VERSION "3.7"

NS_ :

BS_:

BU_: Advantics_Charge_Controller Generic_Power_Modules

BO_ 2147921920 Advantics_Controller_Status: 1 Advantics_Charge_Controller
 SG_ State : 0|8@1+ (1,0) [0|0] "" Vector__XXX

BO_ 2147921921 New_Charge_Session: 2 Advantics_Charge_Controller
 SG_ Plug_and_pins : 8|8@1+ (1,0) [0|0] "" Vector__XXX
 SG_ Communication_Protocol : 0|8@1+ (1,0) [0|0] "" Vector__XXX

BO_ 2147921922 Charge_Status_Change: 1 Advantics_Charge_Controller
 SG_ Vehicle_Ready_for_Charging : 0|8@1+ (1,0) [0|0] "" Vector__XXX

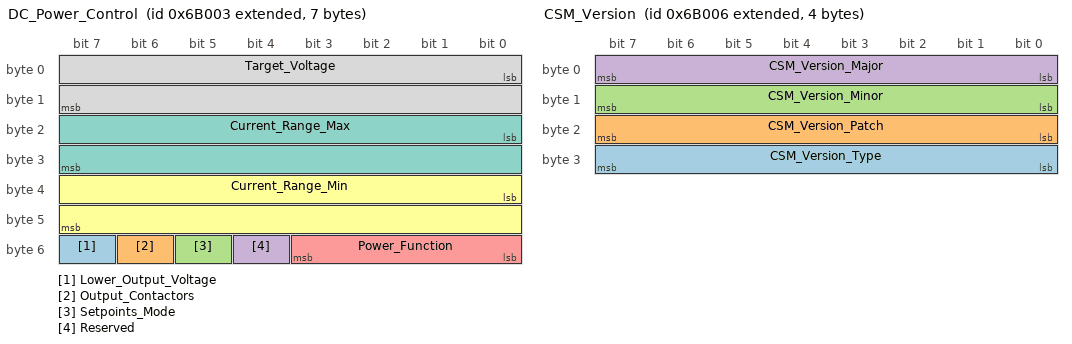
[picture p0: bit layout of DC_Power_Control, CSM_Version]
BO_ 2147921923 DC_Power_Control: 7 Advantics_Charge_Controller
 SG_ Lower_Output_Voltage : 55|1@1+ (1,0) [0|0] "" Vector__XXX
 SG_ Output_Contactors : 54|1@1+ (1,0) [0|0] "" Vector__XXX
 SG_ Setpoints_Mode : 53|1@1+ (1,0) [0|0] "" Vector__XXX
 SG_ Reserved : 52|1@1+ (1,0) [0|0] "" Vector__XXX
 SG_ Power_Function : 48|4@1+ (1,0) [0|0] "" Vector__XXX
 SG_ Current_Range_Min : 32|16@1- (0.1,0) [0|0] "Amps" Vector__XXX
 SG_ Current_Range_Max : 16|16@1- (0.1,0) [0|0] "Amps" Vector__XXX
 SG_ Target_Voltage : 0|16@1+ (0.1,0) [0|0] "Volts" Vector__XXX

BO_ 2147921924 Charge_Session_Finished: 1 Advantics_Charge_Controller
 SG_ State : 0|8@1+ (1,0) [0|0] "" Vector__XXX

BO_ 2147921925 Emergency_Stop: 1 Advantics_Charge_Controller
 SG_ Origin : 0|8@1+ (1,0) [0|0] "" Vector__XXX

BO_ 2147921926 CSM_Version: 4 Advantics_Charge_Controller
 SG_ CSM_Version_Type : 24|8@1+ (1,0) [0|0] "" Vector__XXX
 SG_ CSM_Version_Patch : 16|8@1+ (1,0) [0|0] "" Vector__XXX
 SG_ CSM_Version_Minor : 8|8@1+ (1,0) [0|0] "" Vector__XXX
 SG_ CSM_Version_Major : 0|8@1+ (1,0) [0|0] "" Vector__XXX

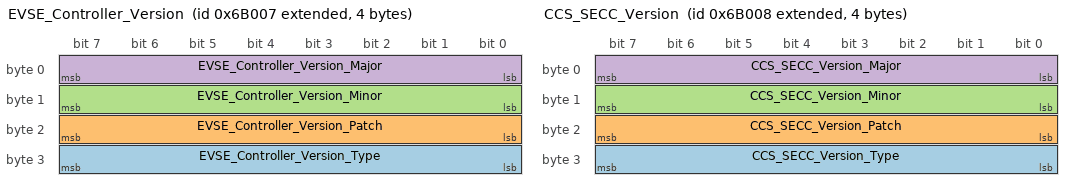
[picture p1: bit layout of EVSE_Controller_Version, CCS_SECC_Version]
BO_ 2147921927 EVSE_Controller_Version: 4 Advantics_Charge_Controller
 SG_ EVSE_Controller_Version_Type : 24|8@1+ (1,0) [0|0] "" Vector__XXX
 SG_ EVSE_Controller_Version_Patch : 16|8@1+ (1,0) [0|0] "" Vector__XXX
 SG_ EVSE_Controller_Version_Minor : 8|8@1+ (1,0) [0|0] "" Vector__XXX
 SG_ EVSE_Controller_Version_Major : 0|8@1+ (1,0) [0|0] "" Vector__XXX

BO_ 2147921928 CCS_SECC_Version: 4 Advantics_Charge_Controller
 SG_ CCS_SECC_Version_Type : 24|8@1+ (1,0) [0|0] "" Vector__XXX
 SG_ CCS_SECC_Version_Patch : 16|8@1+ (1,0) [0|0] "" Vector__XXX
 SG_ CCS_SECC_Version_Minor : 8|8@1+ (1,0) [0|0] "" Vector__XXX
 SG_ CCS_SECC_Version_Major : 0|8@1+ (1,0) [0|0] "" Vector__XXX

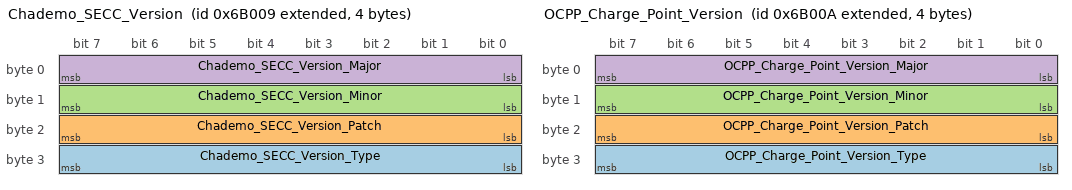
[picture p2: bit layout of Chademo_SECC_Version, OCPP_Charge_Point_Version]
BO_ 2147921929 Chademo_SECC_Version: 4 Advantics_Charge_Controller
 SG_ Chademo_SECC_Version_Type : 24|8@1+ (1,0) [0|0] "" Vector__XXX
 SG_ Chademo_SECC_Version_Patch : 16|8@1+ (1,0) [0|0] "" Vector__XXX
 SG_ Chademo_SECC_Version_Minor : 8|8@1+ (1,0) [0|0] "" Vector__XXX
 SG_ Chademo_SECC_Version_Major : 0|8@1+ (1,0) [0|0] "" Vector__XXX

BO_ 2147921930 OCPP_Charge_Point_Version: 4 Advantics_Charge_Controller
 SG_ OCPP_Charge_Point_Version_Type : 24|8@1+ (1,0) [0|0] "" Vector__XXX
 SG_ OCPP_Charge_Point_Version_Patch : 16|8@1+ (1,0) [0|0] "" Vector__XXX
 SG_ OCPP_Charge_Point_Version_Minor : 8|8@1+ (1,0) [0|0] "" Vector__XXX
 SG_ OCPP_Charge_Point_Version_Major : 0|8@1+ (1,0) [0|0] "" Vector__XXX

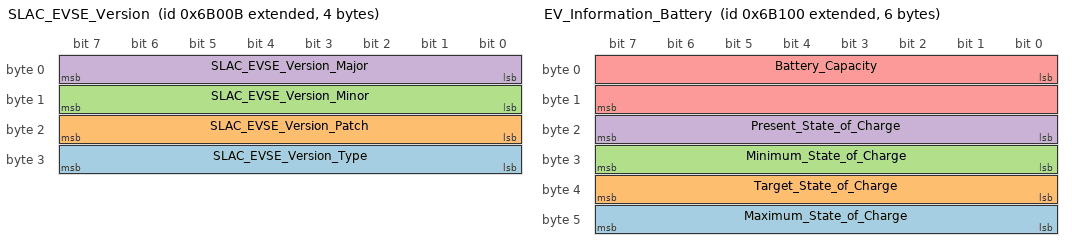
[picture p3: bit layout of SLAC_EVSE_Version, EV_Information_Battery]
BO_ 2147921931 SLAC_EVSE_Version: 4 Advantics_Charge_Controller
 SG_ SLAC_EVSE_Version_Type : 24|8@1+ (1,0) [0|0] "" Vector__XXX
 SG_ SLAC_EVSE_Version_Patch : 16|8@1+ (1,0) [0|0] "" Vector__XXX
 SG_ SLAC_EVSE_Version_Minor : 8|8@1+ (1,0) [0|0] "" Vector__XXX
 SG_ SLAC_EVSE_Version_Major : 0|8@1+ (1,0) [0|0] "" Vector__XXX

BO_ 2147922176 EV_Information_Battery: 6 Advantics_Charge_Controller
 SG_ Maximum_State_of_Charge : 40|8@1+ (1,0) [0|100] "%" Vector__XXX
 SG_ Target_State_of_Charge : 32|8@1+ (1,0) [0|100] "%" Vector__XXX
 SG_ Minimum_State_of_Charge : 24|8@1+ (1,0) [0|100] "%" Vector__XXX
 SG_ Present_State_of_Charge : 16|8@1+ (1,0) [0|100] "%" Vector__XXX
 SG_ Battery_Capacity : 0|16@1+ (1,0) [0|0] "kWh" Vector__XXX

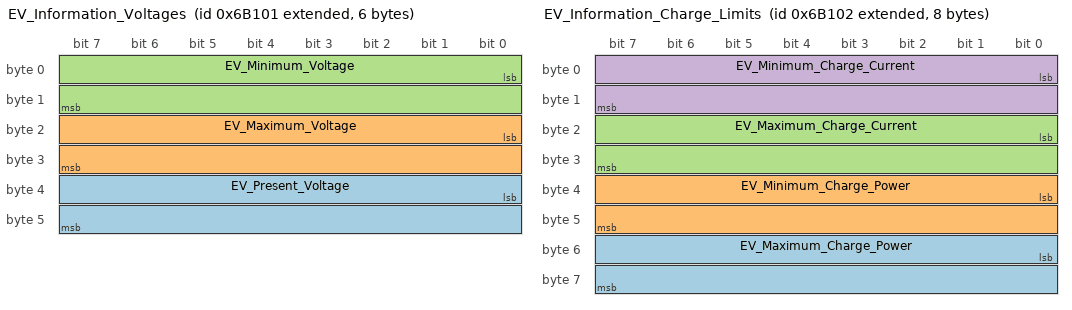
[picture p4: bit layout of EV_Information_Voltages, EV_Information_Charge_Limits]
BO_ 2147922177 EV_Information_Voltages: 6 Advantics_Charge_Controller
 SG_ EV_Present_Voltage : 32|16@1+ (0.1,0) [0|0] "Volts" Vector__XXX
 SG_ EV_Maximum_Voltage : 16|16@1+ (0.1,0) [0|0] "Volts" Vector__XXX
 SG_ EV_Minimum_Voltage : 0|16@1+ (0.1,0) [0|0] "Volts" Vector__XXX

BO_ 2147922178 EV_Information_Charge_Limits: 8 Advantics_Charge_Controller
 SG_ EV_Maximum_Charge_Power : 48|16@1+ (1,0) [0|0] "kW" Vector__XXX
 SG_ EV_Minimum_Charge_Power : 32|16@1+ (1,0) [0|0] "kW" Vector__XXX
 SG_ EV_Maximum_Charge_Current : 16|16@1+ (0.1,0) [0|0] "Amps" Vector__XXX
 SG_ EV_Minimum_Charge_Current : 0|16@1+ (0.1,0) [0|0] "Amps" Vector__XXX

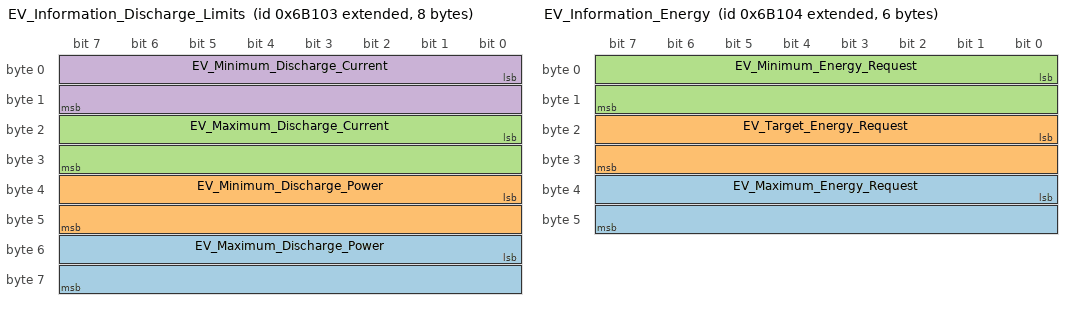
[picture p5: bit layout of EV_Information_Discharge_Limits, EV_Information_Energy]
BO_ 2147922179 EV_Information_Discharge_Limits: 8 Advantics_Charge_Controller
 SG_ EV_Maximum_Discharge_Power : 48|16@1+ (1,0) [0|0] "kW" Vector__XXX
 SG_ EV_Minimum_Discharge_Power : 32|16@1+ (1,0) [0|0] "kW" Vector__XXX
 SG_ EV_Maximum_Discharge_Current : 16|16@1+ (0.1,0) [0|0] "Amps" Vector__XXX
 SG_ EV_Minimum_Discharge_Current : 0|16@1+ (0.1,0) [0|0] "Amps" Vector__XXX

BO_ 2147922180 EV_Information_Energy: 6 Advantics_Charge_Controller
 SG_ EV_Maximum_Energy_Request : 32|16@1- (1,0) [0|0] "kWh" Vector__XXX
 SG_ EV_Target_Energy_Request : 16|16@1- (1,0) [0|0] "kWh" Vector__XXX
 SG_ EV_Minimum_Energy_Request : 0|16@1- (1,0) [0|0] "kWh" Vector__XXX

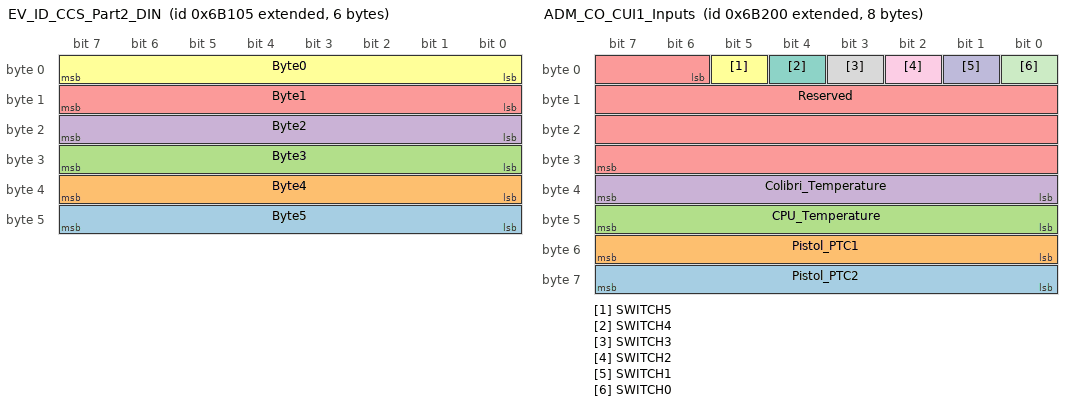
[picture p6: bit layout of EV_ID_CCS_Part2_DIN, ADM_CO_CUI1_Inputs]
BO_ 2147922181 EV_ID_CCS_Part2_DIN: 6 Advantics_Charge_Controller
 SG_ Byte5 : 40|8@1+ (1,0) [0|0] "" Vector__XXX
 SG_ Byte4 : 32|8@1+ (1,0) [0|0] "" Vector__XXX
 SG_ Byte3 : 24|8@1+ (1,0) [0|0] "" Vector__XXX
 SG_ Byte2 : 16|8@1+ (1,0) [0|0] "" Vector__XXX
 SG_ Byte1 : 8|8@1+ (1,0) [0|0] "" Vector__XXX
 SG_ Byte0 : 0|8@1+ (1,0) [0|0] "" Vector__XXX

BO_ 2147922432 ADM_CO_CUI1_Inputs: 8 Advantics_Charge_Controller
 SG_ Pistol_PTC2 : 56|8@1+ (1,-40) [-40|215] "°C" Vector__XXX
 SG_ Pistol_PTC1 : 48|8@1+ (1,-40) [-40|215] "°C" Vector__XXX
 SG_ CPU_Temperature : 40|8@1+ (1,-40) [-40|215] "°C" Vector__XXX
 SG_ Colibri_Temperature : 32|8@1+ (1,-40) [-40|215] "°C" Vector__XXX
 SG_ Reserved : 6|26@1+ (1,0) [0|0] "" Vector__XXX
 SG_ SWITCH5 : 5|1@1+ (1,0) [0|1] "" Vector__XXX
 SG_ SWITCH4 : 4|1@1+ (1,0) [0|1] "" Vector__XXX
 SG_ SWITCH3 : 3|1@1+ (1,0) [0|1] "" Vector__XXX
 SG_ SWITCH2 : 2|1@1+ (1,0) [0|1] "" Vector__XXX
 SG_ SWITCH1 : 1|1@1+ (1,0) [0|1] "" Vector__XXX
 SG_ SWITCH0 : 0|1@1+ (1,0) [0|1] "" Vector__XXX

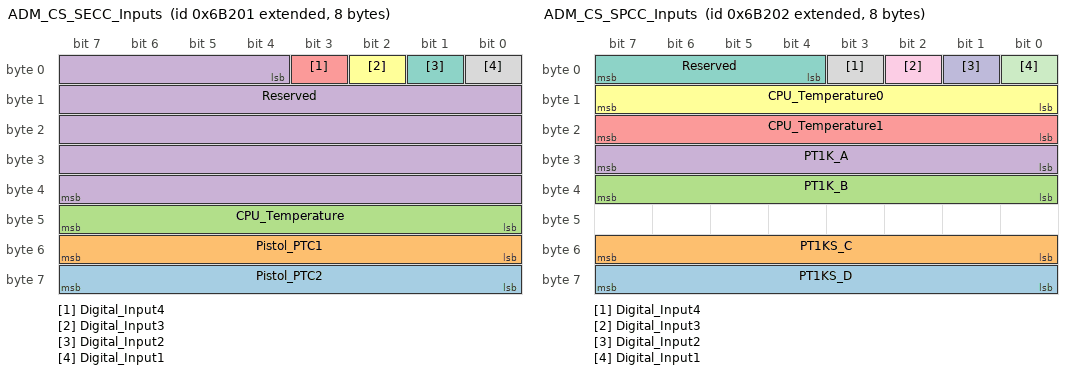
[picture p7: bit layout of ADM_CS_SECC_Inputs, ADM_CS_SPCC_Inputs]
BO_ 2147922433 ADM_CS_SECC_Inputs: 8 Advantics_Charge_Controller
 SG_ Pistol_PTC2 : 56|8@1+ (1,-40) [-40|215] "°C" Vector__XXX
 SG_ Pistol_PTC1 : 48|8@1+ (1,-40) [-40|215] "°C" Vector__XXX
 SG_ CPU_Temperature : 40|8@1+ (1,-40) [-40|215] "°C" Vector__XXX
 SG_ Reserved : 4|36@1+ (1,0) [0|0] "" Vector__XXX
 SG_ Digital_Input4 : 3|1@1+ (1,0) [0|1] "" Vector__XXX
 SG_ Digital_Input3 : 2|1@1+ (1,0) [0|1] "" Vector__XXX
 SG_ Digital_Input2 : 1|1@1+ (1,0) [0|1] "" Vector__XXX
 SG_ Digital_Input1 : 0|1@1+ (1,0) [0|1] "" Vector__XXX

BO_ 2147922434 ADM_CS_SPCC_Inputs: 8 Advantics_Charge_Controller
 SG_ PT1KS_D : 56|8@1+ (1,-40) [-40|215] "°C" Vector__XXX
 SG_ PT1KS_C : 48|8@1+ (1,-40) [-40|215] "°C" Vector__XXX
 SG_ PT1K_B : 32|8@1+ (1,-40) [-40|215] "°C" Vector__XXX
 SG_ PT1K_A : 24|8@1+ (1,-40) [-40|215] "°C" Vector__XXX
 SG_ CPU_Temperature1 : 16|8@1+ (1,-40) [-40|215] "°C" Vector__XXX
 SG_ CPU_Temperature0 : 8|8@1+ (1,-40) [-40|215] "°C" Vector__XXX
 SG_ Reserved : 4|4@1+ (1,0) [0|0] "" Vector__XXX
 SG_ Digital_Input4 : 3|1@1+ (1,0) [0|1] "" Vector__XXX
 SG_ Digital_Input3 : 2|1@1+ (1,0) [0|1] "" Vector__XXX
 SG_ Digital_Input2 : 1|1@1+ (1,0) [0|1] "" Vector__XXX
 SG_ Digital_Input1 : 0|1@1+ (1,0) [0|1] "" Vector__XXX

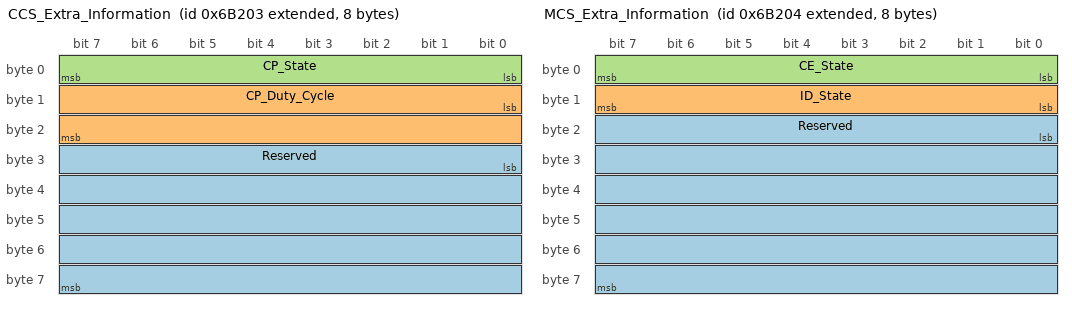
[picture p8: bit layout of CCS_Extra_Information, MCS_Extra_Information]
BO_ 2147922435 CCS_Extra_Information: 8 Advantics_Charge_Controller
 SG_ Reserved : 24|40@1+ (1,0) [0|0] "" Vector__XXX
 SG_ CP_Duty_Cycle : 8|16@1+ (0.1,0) [0|100] "%" Vector__XXX
 SG_ CP_State : 0|8@1+ (1,0) [0|0] "" Vector__XXX

BO_ 2147922436 MCS_Extra_Information: 8 Advantics_Charge_Controller
 SG_ Reserved : 16|48@1+ (1,0) [0|0] "" Vector__XXX
 SG_ ID_State : 8|8@1+ (1,0) [0|0] "" Vector__XXX
 SG_ CE_State : 0|8@1+ (1,0) [0|0] "" Vector__XXX

BO_ 2147922688 OCPP_Control: 2 Advantics_Charge_Controller
 SG_ Dynamic_Target_Current : 0|16@1- (0.1,0) [0|0] "Amps" Vector__XXX

BO_ 2147922944 Charger_Diagnostic_Status: 8 Advantics_Charge_Controller
 SG_ Reserved_Flags : 35|29@1+ (1,0) [0|0] "" Vector__XXX
 SG_ PowerPermitWithdrawn : 34|1@1+ (1,0) [0|0] "" Vector__XXX
 SG_ SessionStoppedBeforeCharge : 33|1@1+ (1,0) [0|0] "" Vector__XXX
 SG_ EVChargingSystemIncompatibility : 32|1@1+ (1,0) [0|0] "" Vector__XXX
 SG_ EVChargingVoltageOutOfRange : 31|1@1+ (1,0) [0|0] "" Vector__XXX
 SG_ EVChargingCurrentDifferential : 30|1@1+ (1,0) [0|0] "" Vector__XXX
 SG_ EVRESSMalfunction : 29|1@1+ (1,0) [0|0] "" Vector__XXX
 SG_ EVConnectorLockFault : 28|1@1+ (1,0) [0|0] "" Vector__XXX
 SG_ EVShiftPosition : 27|1@1+ (1,0) [0|0] "" Vector__XXX
 SG_ EVRESSTemperatureInhibit : 26|1@1+ (1,0) [0|0] "" Vector__XXX
 SG_ CommunicationSetupTimeout : 25|1@1+ (1,0) [0|0] "" Vector__XXX
 SG_ V2GProtocolNotAllowed : 24|1@1+ (1,0) [0|0] "" Vector__XXX
 SG_ V2GParameterNotSupported : 23|1@1+ (1,0) [0|0] "" Vector__XXX
 SG_ V2GSessionIDUnexpected : 22|1@1+ (1,0) [0|0] "" Vector__XXX
 SG_ V2GSequenceError : 21|1@1+ (1,0) [0|0] "" Vector__XXX
 SG_ ChargeEnableStateUnexpected : 20|1@1+ (1,0) [0|0] "" Vector__XXX
 SG_ ChargeEnableFault : 19|1@1+ (1,0) [0|0] "" Vector__XXX
 SG_ ControlPilotStateUnexpected : 18|1@1+ (1,0) [0|0] "" Vector__XXX
 SG_ ControlPilotFault : 17|1@1+ (1,0) [0|0] "" Vector__XXX
 SG_ BidirectionalNotSupported : 16|1@1+ (1,0) [0|0] "" Vector__XXX
 SG_ RangeModeNotSupported : 15|1@1+ (1,0) [0|0] "" Vector__XXX
 SG_ CANBusError : 14|1@1+ (1,0) [0|0] "" Vector__XXX
 SG_ NodeDisconnected : 13|1@1+ (1,0) [0|0] "" Vector__XXX
 SG_ InternalError : 12|1@1+ (1,0) [0|0] "" Vector__XXX
 SG_ ChargerSequenceError : 11|1@1+ (1,0) [0|0] "" Vector__XXX
 SG_ HighTemperature : 10|1@1+ (1,0) [0|0] "" Vector__XXX
 SG_ PowerModuleRampDownTimeout : 9|1@1+ (1,0) [0|0] "" Vector__XXX
 SG_ PowerModuleDisabled : 8|1@1+ (1,0) [0|0] "" Vector__XXX
 SG_ PowerModuleCANTimeout : 7|1@1+ (1,0) [0|0] "" Vector__XXX
 SG_ PowerModuleFault : 6|1@1+ (1,0) [0|0] "" Vector__XXX
 SG_ InsulationMonitorFault : 5|1@1+ (1,0) [0|0] "" Vector__XXX
 SG_ InsulationFault : 4|1@1+ (1,0) [0|0] "" Vector__XXX
 SG_ ConnectorLockFailure : 3|1@1+ (1,0) [0|0] "" Vector__XXX
 SG_ OutputDriverFault : 2|1@1+ (1,0) [0|0] "" Vector__XXX
 SG_ EmergencyStopLoopOpen : 1|1@1+ (1,0) [0|0] "" Vector__XXX
 SG_ InterlockFault : 0|1@1+ (1,0) [0|0] "" Vector__XXX

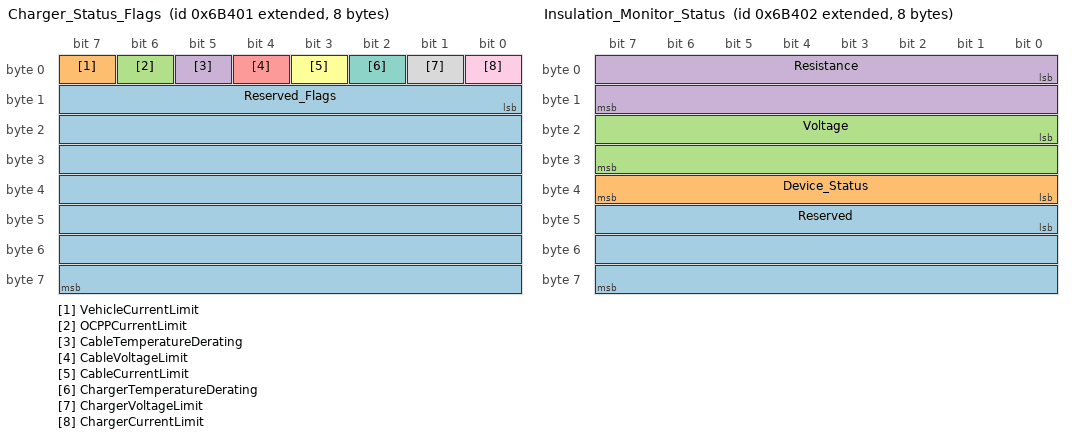
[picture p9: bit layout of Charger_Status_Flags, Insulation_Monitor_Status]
BO_ 2147922945 Charger_Status_Flags: 8 Advantics_Charge_Controller
 SG_ Reserved_Flags : 8|56@1+ (1,0) [0|0] "" Vector__XXX
 SG_ VehicleCurrentLimit : 7|1@1+ (1,0) [0|0] "" Vector__XXX
 SG_ OCPPCurrentLimit : 6|1@1+ (1,0) [0|0] "" Vector__XXX
 SG_ CableTemperatureDerating : 5|1@1+ (1,0) [0|0] "" Vector__XXX
 SG_ CableVoltageLimit : 4|1@1+ (1,0) [0|0] "" Vector__XXX
 SG_ CableCurrentLimit : 3|1@1+ (1,0) [0|0] "" Vector__XXX
 SG_ ChargerTemperatureDerating : 2|1@1+ (1,0) [0|0] "" Vector__XXX
 SG_ ChargerVoltageLimit : 1|1@1+ (1,0) [0|0] "" Vector__XXX
 SG_ ChargerCurrentLimit : 0|1@1+ (1,0) [0|0] "" Vector__XXX

BO_ 2147922946 Insulation_Monitor_Status: 8 Advantics_Charge_Controller
 SG_ Reserved : 40|24@1+ (1,0) [0|0] "" Vector__XXX
 SG_ Device_Status : 32|8@1+ (1,0) [0|0] "" Vector__XXX
 SG_ Voltage : 16|16@1+ (1,0) [0|0] "Volts" Vector__XXX
 SG_ Resistance : 0|16@1+ (1,0) [0|0] "kOhms" Vector__XXX

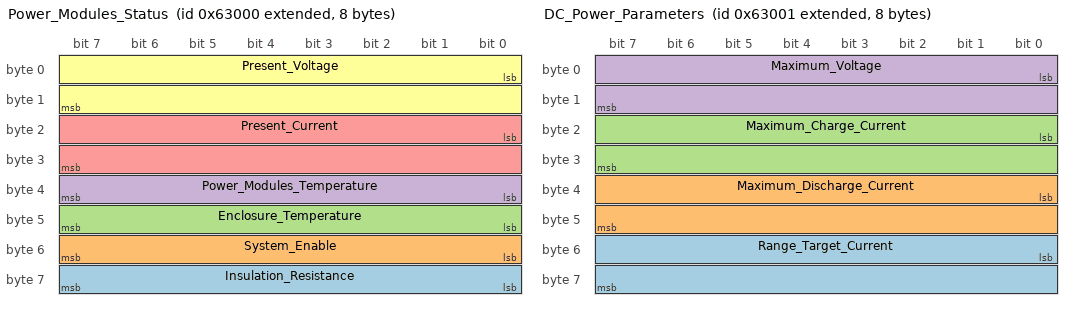
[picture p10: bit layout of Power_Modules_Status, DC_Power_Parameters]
BO_ 2147889152 Power_Modules_Status: 8 Generic_Power_Modules
 SG_ Insulation_Resistance : 56|8@1+ (2,0) [0|0] "kOhms" Vector__XXX
 SG_ System_Enable : 48|8@1+ (1,0) [0|0] "" Vector__XXX
 SG_ Enclosure_Temperature : 40|8@1+ (1,-40) [-40|215] "°C" Vector__XXX
 SG_ Power_Modules_Temperature : 32|8@1+ (1,-40) [-40|215] "°C" Vector__XXX
 SG_ Present_Current : 16|16@1- (0.1,0) [0|0] "Amps" Vector__XXX
 SG_ Present_Voltage : 0|16@1+ (0.1,0) [0|0] "Volts" Vector__XXX

BO_ 2147889153 DC_Power_Parameters: 8 Generic_Power_Modules
 SG_ Range_Target_Current : 48|16@1- (0.1,0) [0|0] "Amps" Vector__XXX
 SG_ Maximum_Discharge_Current : 32|16@1+ (0.1,0) [0|0] "Amps" Vector__XXX
 SG_ Maximum_Charge_Current : 16|16@1+ (0.1,0) [0|0] "Amps" Vector__XXX
 SG_ Maximum_Voltage : 0|16@1+ (0.1,0) [0|0] "Volts" Vector__XXX

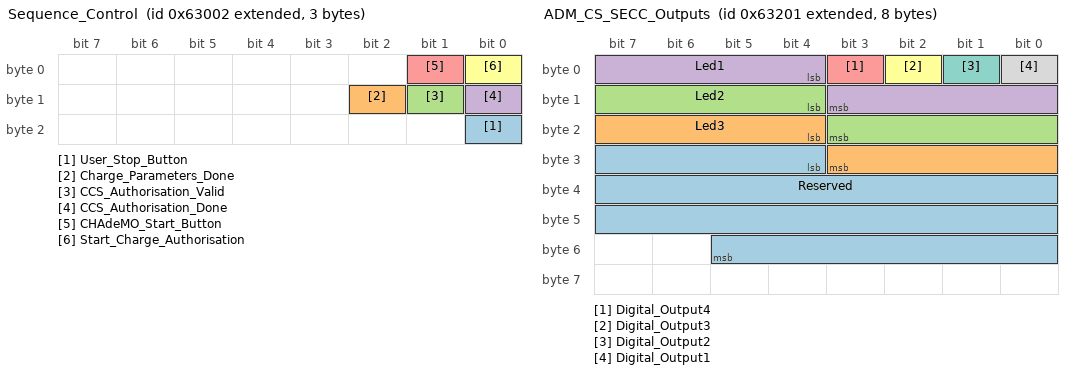
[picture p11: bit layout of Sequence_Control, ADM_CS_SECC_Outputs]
BO_ 2147889154 Sequence_Control: 3 Generic_Power_Modules
 SG_ User_Stop_Button : 16|1@1+ (1,0) [0|0] "" Vector__XXX
 SG_ Charge_Parameters_Done : 10|1@1+ (1,0) [0|0] "" Vector__XXX
 SG_ CCS_Authorisation_Valid : 9|1@1+ (1,0) [0|0] "" Vector__XXX
 SG_ CCS_Authorisation_Done : 8|1@1+ (1,0) [0|0] "" Vector__XXX
 SG_ CHAdeMO_Start_Button : 1|1@1+ (1,0) [0|0] "" Vector__XXX
 SG_ Start_Charge_Authorisation : 0|1@1+ (1,0) [0|0] "" Vector__XXX

BO_ 2147889665 ADM_CS_SECC_Outputs: 8 Generic_Power_Modules
 SG_ Reserved : 28|26@1+ (1,0) [0|0] "" Vector__XXX
 SG_ Led3 : 20|8@1+ (1,0) [0|255] "" Vector__XXX
 SG_ Led2 : 12|8@1+ (1,0) [0|255] "" Vector__XXX
 SG_ Led1 : 4|8@1+ (1,0) [0|255] "" Vector__XXX
 SG_ Digital_Output4 : 3|1@1+ (1,0) [0|1] "" Vector__XXX
 SG_ Digital_Output3 : 2|1@1+ (1,0) [0|1] "" Vector__XXX
 SG_ Digital_Output2 : 1|1@1+ (1,0) [0|1] "" Vector__XXX
 SG_ Digital_Output1 : 0|1@1+ (1,0) [0|1] "" Vector__XXX

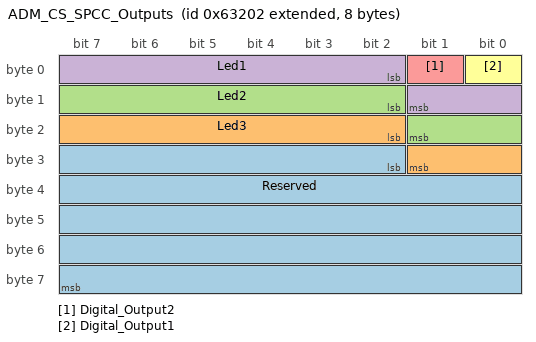
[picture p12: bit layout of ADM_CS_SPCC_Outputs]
BO_ 2147889666 ADM_CS_SPCC_Outputs: 8 Generic_Power_Modules
 SG_ Reserved : 26|38@1+ (1,0) [0|0] "" Vector__XXX
 SG_ Led3 : 18|8@1+ (1,0) [0|255] "" Vector__XXX
 SG_ Led2 : 10|8@1+ (1,0) [0|255] "" Vector__XXX
 SG_ Led1 : 2|8@1+ (1,0) [0|255] "" Vector__XXX
 SG_ Digital_Output2 : 1|1@1+ (1,0) [0|1] "" Vector__XXX
 SG_ Digital_Output1 : 0|1@1+ (1,0) [0|1] "" Vector__XXX

CM_ BO_ 2147921920 "
                Periodic message reporting the current status of the controller. This message is
                sent all the time as soon as the application on the controller is running.

                IMPORTANT: Power modules should implement a timeout on the reception of this message.
                If the controller does not send this message within 200 ms, then power modules
                should consider the controller to be in a defective state and stop any power function
                as soon as possible.
            ";
CM_ SG_ 2147921920 State "
                    Current internal state. For information only.

                    Initialising:: Controller's applications are starting up.
                    Waiting_For_PEV:: Controller is idle and ready for a plug-in.
                    Negotiating_Connection:: Controller is plugged to a car and the connection is
                        being initialised. Important charge information are exchanged.
                    Connected_With_Full_Info:: All charge information from the PEV were retrieved
                        and a charge session can be considered to be properly open.
                    Insulation_Test:: Insulation of the charge cable is being tested.
                    Precharge:: Charger is matching its output voltage to the present voltage of the
                        battery.
                    Waiting_For_Charge:: PEV is about to begin the actual charging.
                    Charging:: Main charging loop going on.
                    Ending_Charge:: A normal charge stop condition happenned and the PEV is exiting
                        the charging loop.
                    Welding_Detection:: PEV is testing if its contactors are welded.
                    Closing_Communication:: PEV can unplug and charger is reinitialising in order to
                        then go back to __Waiting_For_PEV__.
                    CCS_Authorisation_Process:: Special state in CCS to authorise user.
                    Not_Available:: Controller has been made unavailable by
                        __Sequence_Control.Start_Charge_Authorisation__
                ";
CM_ BO_ 2147921921 "
                Information about an incoming vehicle. Sent periodically from the moment a car is
                plugged in and all the information are known. Until power modules send a
                <<Power_Modules_Status.System_Enable>> with value  __Allowed__.
            ";
CM_ SG_ 2147921921 Plug_and_pins "Plug type and DC pins selected by the car.";
CM_ SG_ 2147921921 Communication_Protocol "The charging protocol the car is using.";
CM_ BO_ 2147921922 "
                Signal a change in the charging procedure. Sent once only when something change.
            ";
CM_ SG_ 2147921922 Vehicle_Ready_for_Charging "
                    Tells when the vehicle intend to start or stop the charge.

                    If value is __Charge_Started__, the power modules must be ready for the
                    charging loop at any moment (with CCS it can still be in several hours).

                    When value is __Charge_Stopped__, the vehicle stopped the charging process.
                ";
CM_ BO_ 2147921923 "
                Sent during any powered phase of a DC charge session. This message contains the
                power function in use, setpoint targets or range, the setpoints mode, the output
                contactors and voltage lowering commands.

                # Power function

                The power function currently in use is given by <<DC_Power_Control.Power_Function>>.
                It covers the off state, standby, insulation test, precharge and the actual power
                transfer.

                During __Standby__, power modules should disable any power processing function (ie.
                turn off), but not bleed their output capacitors (ie. leave the output floating) as
                a load might be connected at that time, unless otherwise commanded by
                <<DC_Power_Control.Lower_Output_Voltage>>.

                During __Insulation_Test__, the insulation of the cable is tested by applying a
                voltage from the charger. The battery is not connected yet. The test voltage to
                apply is given by <<DC_Power_Control.Target_Voltage>>. Power modules report
                <<Power_Modules_Status.Present_Voltage>> and <<Power_Modules_Status.Insulation_Resistance>>
                and the controller decides when the test passes or fails. Safety standards require a
                minimum of 100 Ohms/V insulation resistance. With a typical test voltage of 500 V,
                insulation resistance should be >= 50 kOhms. Maximum current to use is not specified.

                During __Precharge__ (CCS only), charger is expected to match battery voltage at its
                output while having no load, apart from capacitors on the line. When charging this
                capacitive load, it shall not output more current than <<DC_Power_Control.Current_Range_Max>>.
                The battery voltage to match is given by <<DC_Power_Control.Target_Voltage>>. The
                vehicle decides to consider precharge done when it senses on its inlet a voltage that
                is +/- 20 V of its battery voltage.

                During __Power_Transfer__, actual power is being transfered in one direction or
                another. The meaning of setpoints depends on <<DC_Power_Control.Setpoints_Mode>>.
                The transfer direction depends on the sign of current setpoints, with positive
                meaning power being delivered to the vehicle (ie. charge). And negative meaning
                power extracted from the vehicle (ie. discharge).

                NOTE: While targets and ranges are expressed in both voltage and current, it is up
                to power modules to determine which control mode they should use (ie. constant current,
                constant voltage or constant power) depending on the present situation, and the load
                attached to their output. Charging protocols do not define it. In a typical situation,
                insulation tests and precharge have to be controlled in Constant Voltage. Whereas,
                when a battery is connected to the charger output, the vehicle BMS specifies the
                maximum current to be delivered to it, or consummed from it. Which makes it a
                Constant Current process. But you might also encounter a vehicle with a different
                pack voltage (eg. 800 V), and using a DC/DC in between the charger output and its
                battery to convert the voltage. In such case, you might have to run into Constant
                Voltage mode for instance.

                # Setpoints mode

                Either the vehicle control the current to be delivered or consummed (that's
                __Target_Mode__). Or, a range of acceptable values is given, and power modules are
                free to operate within that range (that's __Range_Mode__).

                In the simplest (historical) case, power transfer is unidirectional, with the
                vehicle requesting a certain amount of current for a target voltage, and power
                modules have to deliver that current. __Target_Mode__ is used in that case.
                And both min and max of the range have the same value. If you do less current than
                requested, some vehicle might accept it, and some might terminate the charge on a
                current deviation error. <<Power_Transfer_Parameters.Maximum_Charge_Current>> offers
                a way to dynamically \"negotiate\" a lower current request properly.

                If the vehicle and/or charging protocol wants to use limits instead of targets (eg.
                CHAdeMO V2G, or ISO 15118-20 in Dynamic mode), then __Range_Mode__ is used. The min
                and max of the range are given, and power modules can choose the actual load and
                power transfer direction within that range.

                Note however that, if in your application power modules are not able to decide of
                the load by themselves, then you can treat the maximum of the range as the target
                setpoint (which is why the same signal is used for both target and maximum).

                During a power transfer, the setpoint mode does not change between range or target.
                However, during the rest of the session, for consistency, during __Insulation_Test__
                it will be __Target_Mode__. And during __Precharge__ it will be __Range_Mode__.
                During other power functions it is not relevant.

                # Bidirectional power transfers

                Bidirectional power transfers are only possible when both the vehicle and the charger
                supports it (on charger side, `is_bidirectional` has to be set to True in the config
                file for that pistol). Bidirectional power transfer can happen either in
                __Range_Mode__ (power modules choose when to switch over) or __Target_Mode__ (vehicle
                decides when it is time to charge or discharge its battery). Bidirectional in range
                mode would typically happen with CHAdeMO V2G, or ISO 15118-20 in Dynamic mode.
                Whereas birectional in target mode would happen with ISO 15118-20 in Scheduled mode.

                When in range mode, a portion of the range will be in the negative values (or all of
                it if only discharge is possible). Note that the positive portion of the range, used
                for charging, naturally follows min and max charge current values. Whereas the
                negative portion of the range, used for discharging, is mirrored, and its min and
                max are logically inverted. Said differently <<DC_Power_Control.Current_Range_Min>>
                shows the maximum discharge current, but with a negative sign. And
                <<DC_Power_Control.Current_Range_Max>> shows the maximum charge current with a
                positive sign.

                In the particular situation only discharge is possible, the minimum of the range is
                still the maximum discharge current with a negative sign. And the maximum of the
                range is then the minimum discharge current, also with a negative sign.

                As such, you can see this range as a \"continuous slider\" on which you can pick an
                operating point, moving between the maximum discharge current (the min), and the
                maximum charge current (the max). With 0 as a midpoint (but not necessarily
                symmetric). If no discharge is possible, then the min is positive. And if no charge
                is possible, then the max is negative.

                WARNING: The vehicle might not necessarily ramps up or down its requests.
            ";
CM_ SG_ 2147921923 Lower_Output_Voltage "
                    Tells when charger output voltage should forcibly be lowered to less than or
                    equal to 20 V. It can be done, for instance, by bleeding the voltage of power
                    modules output capacitors.

                    Can only happen in __Standby__ function, with voltage and current setpoints set
                    to 0.

                    Output voltage lowering is requested at the following points in the charge
                    session:

                    - After insulation test, and before precharge (CCS) or power transfer (CHAdeMO).
                      In this case, the controller does not command output contactors to open by
                      itself (ie. using its onboard relay) as they would have to reclose shortly
                      after. It will however wait that output voltage lower to <= 20 V to comply
                      with charging standards.
                    - After power transfer, when <<Advantics_Controller_Status.State>> is
                      __Ending_Charge__, current has lowered to less than 1 A, and after having
                      opened output contactors. In this case, the controller does not need to wait
                      for voltage to lower. Note that at this point the vehicle battery might still
                      be connected to pistol pins (hence why it does not wait on the voltage). Which
                      means if your charger does not have output contactors, you should actually
                      avoid bleeding output capacitors at this point, and ignore the lowering request.
                    - When entering <<Advantics_Controller_Status.State>> == __Closing_Communication__
                      if output voltage is above 20 V. It could happen after a welding detection
                      process from the vehicle in case there are no output contactors and output
                      capacitors are still charged (or got recharged during welding detection). This
                      lowering request is for safety, in order to avoid exposing high voltages on
                      the pistol contacts once it gets unplugged from the vehicle.
                ";
CM_ SG_ 2147921923 Output_Contactors "
                    Reflects contactors control done using controller's onboard relay.
                ";
CM_ SG_ 2147921923 Setpoints_Mode "
                    Defines how power modules should follow setpoints.

                    __Target_Mode__: Power transfer is controlled by the vehicle, and power modules
                    should follow the given targets. Min and max of the range have the same value.

                    __Range_Mode__: All parties provide ranges of acceptable limits, and the
                    controller gives a merged view of that range. Power modules are then free to
                    provide or draw power within that range.
                ";
CM_ SG_ 2147921923 Reserved "Reserved bits for future uses.";
CM_ SG_ 2147921923 Power_Function "
                    This signal describes the sort of power function expected from power modules at
                    a particular point in the process.

                    __Off__: Power modules turn off any power processing function. And the output of
                    the charger (exposed on the pistol pins) has ~0 V, floating.

                    __Standby__: Power modules do not run any power processing function, while
                    remaining ready to receive future requests. A load might still be connected to
                    their output. Therefore, unless comanded by <<DC_Power_Control.Lower_Output_Voltage>>,
                    it should remain floating, with contactors still closed, and no discharge of
                    their output capacitors should be attempted.

                    __Insulation_Test__: Power modules (or an external dedicated safety module) apply
                    high voltage and measure the current leaked through ground. The test voltage
                    reaches up to the vehicle, but its input contactors are still open.

                    __Precharge__: Power modules match the requested voltage while limiting their
                    output current (only some capacitance should be charged during this process).
                    The purpose is to avoid arcing when vehicle contactors close.
                    Precharge is specific to CCS. In CHAdeMO you either have a diode at the output
                    of the charger (unidirectional). Or a custom precharge circuit around the main
                    output contactors (bidirectionnal, or unidirectional made without diode).

                    __Power_Transfer__: Main mode of operation, as power is being transfered in one
                    way or another. See the documentation of <<DC_Power_Control.Setpoints_Mode>> and
                    others signals of this message for more details.
                ";
CM_ SG_ 2147921923 Current_Range_Min "
                    Maximum current to draw (if negative), or minimum current to provide (if positive).

                    In __Target_Mode__, this signal will have the same value than
                    <<DC_Power_Control.Current_Range_Max>>.

                    In __Insulation_Test__, this signal is not relevant.

                    In __Precharge__, this signal is 0 A.

                    In __Power_Transfer__, this signal gives the minimum of the current range to use.
                ";
CM_ SG_ 2147921923 Current_Range_Max "
                    Maximum current to provide (if positive), or minimum current to draw (if negative).

                    In __Target_Mode__, this signal should be used as the target current setpoint.

                    In __Insulation_Test__, this signal is not relevant.

                    In __Precharge__, this signal carries the maximum current the vehicle wants
                    charger to respect. Usually a value between 0 and 2 A.

                    In __Power_Transfer__, this signal gives the maximum of the current range to use.
                ";
CM_ SG_ 2147921923 Target_Voltage "
                    Voltage setpoint.

                    In __Insulation_Test__, this is the test voltage, and it should corresponds to
                    the maximum voltage a charger can theoretically deliver during a charge session.
                    At the end of the test, this setpoint is set back to 0 V.

                    In __Precharge__, it usually corresponds to the real battery voltage (unless the
                    vehicle uses an intermediate DC/DC).

                    In __Power_Transfer__, it usually corresponds to a voltage significantly higher
                    than the battery voltage (implying a Constant Current process). However, if the
                    vehicle uses an intermediate DC/DC, then it corresponds to the input voltage of
                    that DC/DC.
                ";
CM_ BO_ 2147921924 "Charging is over and the vehicle should unplug soon.";
CM_ SG_ 2147921924 State "Was the session terminated cleanly or not.";
CM_ BO_ 2147921925 "
                Sent from the moment an emergency stop has been triggered.

                Emergency_Stop are not explicitly rearmable. You either power cycle the whole setup.
                Or the emergency condition disappear, and the message will stop being sent once the
                controller pass in a state where it reevaluates emergency conditions.
            ";
CM_ SG_ 2147921925 Origin "From which side the emergency stop came from.";
CM_ BO_ 2147921926 "
                Reports the software version of the CSM (Charge Station Management) application.

                Sent periodically once the application is running. Versions rarely change (a new
                version requires restarting the application), so a slow polling interval on the
                receiving side is fine.
            ";
CM_ SG_ 2147921926 CSM_Version_Type "Release type of the CSM application version.";
CM_ SG_ 2147921926 CSM_Version_Patch "Patch version number of the CSM application.";
CM_ SG_ 2147921926 CSM_Version_Minor "Minor version number of the CSM application.";
CM_ SG_ 2147921926 CSM_Version_Major "Major version number of the CSM application.";
CM_ BO_ 2147921927 "
                Reports the software version of the EVSE controller application itself.

                Sent periodically once the application is running. Versions rarely change (a new
                version requires restarting the application), so a slow polling interval on the
                receiving side is fine.
            ";
CM_ SG_ 2147921927 EVSE_Controller_Version_Type "Release type of the EVSE controller application version.";
CM_ SG_ 2147921927 EVSE_Controller_Version_Patch "Patch version number of the EVSE controller application.";
CM_ SG_ 2147921927 EVSE_Controller_Version_Minor "Minor version number of the EVSE controller application.";
CM_ SG_ 2147921927 EVSE_Controller_Version_Major "Major version number of the EVSE controller application.";
CM_ BO_ 2147921928 "
                Reports the software version of the CCS SECC (Supply Equipment Communication
                Controller) application.

                Sent periodically once the application is running. Only relevant on installations
                that have CCS enabled; otherwise reported as 0.0.0.
            ";
CM_ SG_ 2147921928 CCS_SECC_Version_Type "Release type of the CCS SECC application version.";
CM_ SG_ 2147921928 CCS_SECC_Version_Patch "Patch version number of the CCS SECC application.";
CM_ SG_ 2147921928 CCS_SECC_Version_Minor "Minor version number of the CCS SECC application.";
CM_ SG_ 2147921928 CCS_SECC_Version_Major "Major version number of the CCS SECC application.";
CM_ BO_ 2147921929 "
                Reports the software version of the CHAdeMO SECC (Supply Equipment Communication
                Controller) application.

                Sent periodically once the application is running. Only relevant on installations
                that have CHAdeMO enabled; otherwise reported as 0.0.0.
            ";
CM_ SG_ 2147921929 Chademo_SECC_Version_Type "Release type of the CHAdeMO SECC application version.";
CM_ SG_ 2147921929 Chademo_SECC_Version_Patch "Patch version number of the CHAdeMO SECC application.";
CM_ SG_ 2147921929 Chademo_SECC_Version_Minor "Minor version number of the CHAdeMO SECC application.";
CM_ SG_ 2147921929 Chademo_SECC_Version_Major "Major version number of the CHAdeMO SECC application.";
CM_ BO_ 2147921930 "
                Reports the software version of the OCPP charge point application.

                Sent periodically once the application is running. Versions rarely change (a new
                version requires restarting the application), so a slow polling interval on the
                receiving side is fine.
            ";
CM_ SG_ 2147921930 OCPP_Charge_Point_Version_Type "Release type of the OCPP charge point application version.";
CM_ SG_ 2147921930 OCPP_Charge_Point_Version_Patch "Patch version number of the OCPP charge point application.";
CM_ SG_ 2147921930 OCPP_Charge_Point_Version_Minor "Minor version number of the OCPP charge point application.";
CM_ SG_ 2147921930 OCPP_Charge_Point_Version_Major "Major version number of the OCPP charge point application.";
CM_ BO_ 2147921931 "
                Reports the software version of the SLAC (Signal Level Attenuation
                Characterization) EVSE application.

                Sent periodically once the application is running. Versions rarely change (a new
                version requires restarting the application), so a slow polling interval on the
                receiving side is fine.
            ";
CM_ SG_ 2147921931 SLAC_EVSE_Version_Type "Release type of the SLAC EVSE application version.";
CM_ SG_ 2147921931 SLAC_EVSE_Version_Patch "Patch version number of the SLAC EVSE application.";
CM_ SG_ 2147921931 SLAC_EVSE_Version_Minor "Minor version number of the SLAC EVSE application.";
CM_ SG_ 2147921931 SLAC_EVSE_Version_Major "Major version number of the SLAC EVSE application.";
CM_ BO_ 2147922176 "
                Vehicle battery information.

                Sent at least once after first <<New_Charge_Session>> message. As well as every time
                vehicle changes these information.

                Many of these information can be optional. There default value is 0 if the vehicle
                did not sent them.
            ";
CM_ SG_ 2147922176 Maximum_State_of_Charge "Maximum battery SoC vehicle wants, in percent.";
CM_ SG_ 2147922176 Target_State_of_Charge "Target battery SoC vehicle wants, in percent.";
CM_ SG_ 2147922176 Minimum_State_of_Charge "Minimum battery SoC vehicle wants, in percent.";
CM_ SG_ 2147922176 Present_State_of_Charge "Battery SoC, in percent.";
CM_ SG_ 2147922176 Battery_Capacity "Total battery capacity.";
CM_ BO_ 2147922177 "
                Vehicle voltages information.

                Sent at least once after first <<New_Charge_Session>> message. As well as every time
                vehicle changes these information.

                Many of these information can be optional. There default value is 0 if the vehicle
                did not sent them.
            ";
CM_ SG_ 2147922177 EV_Present_Voltage "
                    Present voltage reported by vehicle.

                    Note: Can be use in Constant Voltage mode to compensate for cable losses.
                ";
CM_ SG_ 2147922177 EV_Maximum_Voltage "Maximum vehicle voltage.";
CM_ SG_ 2147922177 EV_Minimum_Voltage "Minimum vehicle voltage.";
CM_ BO_ 2147922178 "
                Vehicle information for current and power limits during charging.

                Sent at least once after first <<New_Charge_Session>> message. As well as every time
                vehicle changes these information.

                Many of these information can be optional. There default value is 0 if the vehicle
                did not sent them.
            ";
CM_ SG_ 2147922178 EV_Maximum_Charge_Power "Maximum vehicle charge power.";
CM_ SG_ 2147922178 EV_Minimum_Charge_Power "Minimum vehicle charge power.";
CM_ SG_ 2147922178 EV_Maximum_Charge_Current "Maximum vehicle charge current.";
CM_ SG_ 2147922178 EV_Minimum_Charge_Current "Minimum vehicle charge current.";
CM_ BO_ 2147922179 "
                Vehicle information for current and power limits during discharging.

                Sent at least once after first <<New_Charge_Session>> message. As well as every time
                vehicle changes these information.

                Many of these information can be optional. There default value is 0 if the vehicle
                did not sent them.
            ";
CM_ SG_ 2147922179 EV_Maximum_Discharge_Power "Maximum vehicle discharge power.";
CM_ SG_ 2147922179 EV_Minimum_Discharge_Power "Minimum vehicle discharge power.";
CM_ SG_ 2147922179 EV_Maximum_Discharge_Current "Maximum vehicle discharge current.";
CM_ SG_ 2147922179 EV_Minimum_Discharge_Current "Minimum vehicle discharge current.";
CM_ BO_ 2147922180 "
                Vehicle information for energy.

                Sent at least once after first <<New_Charge_Session>> message. As well as every time
                vehicle changes these information.

                Many of these information can be optional. There default value is 0 if the vehicle
                did not sent them.
            ";
CM_ SG_ 2147922180 EV_Maximum_Energy_Request "
                    Maximum (estimated) remaining energy vehicle will consumme (positive value),
                    or provide (negative value).
                ";
CM_ SG_ 2147922180 EV_Target_Energy_Request "
                    Targeted (estimated) remaining energy vehicle will consumme (positive value),
                    or provide (negative value).
                ";
CM_ SG_ 2147922180 EV_Minimum_Energy_Request "
                    Minimum (estimated) remaining energy vehicle will consumme (positive value),
                    or provide (negative value).
                ";
CM_ BO_ 2147922181 "
                The EV ID provided by the vehicle in CCS DIN SPEC 70121 and ISO 15118-2.
                EV ID for CCS ISO 15118-20 is not supported by this message.
                (the EV ID is defined as a string of max 255 characters in ISO 15118-20)
            ";
CM_ SG_ 2147922181 Byte5 "
                    Byte 5 of the EV ID.
                ";
CM_ SG_ 2147922181 Byte4 "
                    Byte 4 of the EV ID.
                ";
CM_ SG_ 2147922181 Byte3 "
                    Byte 3 of the EV ID.
                ";
CM_ SG_ 2147922181 Byte2 "
                    Byte 2 of the EV ID.
                ";
CM_ SG_ 2147922181 Byte1 "
                    Byte 1 of the EV ID.
                ";
CM_ SG_ 2147922181 Byte0 "
                    Byte 0 of the EV ID.
                ";
CM_ BO_ 2147922432 "
                Controller (ADM-CO-CUI1 hardware variant, ie. \"generic/mobile\") is reporting various
                information about its inputs. It is sent every seconds (for temperature channels).
                Or on change for other digital inputs.
            ";
CM_ SG_ 2147922432 Pistol_PTC2 "Measured temperature sensor on second PTC channel associated to this pistol.";
CM_ SG_ 2147922432 Pistol_PTC1 "Measured temperature sensor on first PTC channel associated to this pistol.";
CM_ SG_ 2147922432 CPU_Temperature "Temperature reported by the CPU chip of the charge controller.";
CM_ SG_ 2147922432 Colibri_Temperature "Temperature measured on the Colibri SoM board of the charge controller.";
CM_ SG_ 2147922432 Reserved "Reserved bits for future uses.";
CM_ SG_ 2147922432 SWITCH5 "
                    Reports the logical state of SWITCH5 (J7, position 6).
                    Needs to be declared as monitored in `/srv/config.cfg`:

                        [hardware]
                        switch5 = Monitor
                ";
CM_ SG_ 2147922432 SWITCH4 "
                    Reports the logical state of SWITCH4 (J7, position 5).
                    Needs to be declared as monitored in `/srv/config.cfg`:

                        [hardware]
                        switch4 = Monitor
                ";
CM_ SG_ 2147922432 SWITCH3 "
                    Reports the logical state of SWITCH3 (J7, position 4).
                    Needs to be declared as monitored in `/srv/config.cfg`:

                        [hardware]
                        switch3 = Monitor
                ";
CM_ SG_ 2147922432 SWITCH2 "
                    Reports the logical state of SWITCH2 (J7, position 3).
                    Needs to be declared as monitored in `/srv/config.cfg`:

                        [hardware]
                        switch2 = Monitor
                ";
CM_ SG_ 2147922432 SWITCH1 "
                    Reports the logical state of SWITCH1 (J7, position 2).
                    Needs to be declared as monitored in `/srv/config.cfg`:

                        [hardware]
                        switch1 = Monitor
                ";
CM_ SG_ 2147922432 SWITCH0 "
                    Reports the logical state of SWITCH0 (J7, position 1).
                    Needs to be declared as monitored in `/srv/config.cfg`:

                        [hardware]
                        switch0 = Monitor
                ";
CM_ BO_ 2147922433 "
                Controller (ADM-CS-SECC hardware variant, ie. \"DIN rail\") is reporting various
                information about its inputs. It is sent every seconds (for temperature channels).
                Or on change for other digital inputs.
            ";
CM_ SG_ 2147922433 Pistol_PTC2 "Measured temperature sensor on second PTC channel associated to this pistol.";
CM_ SG_ 2147922433 Pistol_PTC1 "Measured temperature sensor on first PTC channel associated to this pistol.";
CM_ SG_ 2147922433 CPU_Temperature "Temperature reported by the CPU chip of the charge controller.";
CM_ SG_ 2147922433 Reserved "Reserved bits for future uses.";
CM_ SG_ 2147922433 Digital_Input4 "
                    Reports the logical state of DIG_IN4 (CONN6, position 4).
                    Needs to be declared as monitored in `/srv/config.cfg`:

                        [hardware]
                        dig_in4 = Monitor
                ";
CM_ SG_ 2147922433 Digital_Input3 "
                    Reports the logical state of DIG_IN3 (CONN6, position 3).
                    Needs to be declared as monitored in `/srv/config.cfg`:

                        [hardware]
                        dig_in3 = Monitor
                ";
CM_ SG_ 2147922433 Digital_Input2 "
                    Reports the logical state of DIG_IN2 (CONN6, position 2).
                    Needs to be declared as monitored in `/srv/config.cfg`:

                        [hardware]
                        dig_in2 = Monitor
                ";
CM_ SG_ 2147922433 Digital_Input1 "
                    Reports the logical state of DIG_IN1 (CONN6, position 1).
                    Needs to be declared as monitored in `/srv/config.cfg`:

                        [hardware]
                        dig_in1 = Monitor
                ";
CM_ BO_ 2147922434 "
                Controller (ADM-CS-SPCC hardware variant) is reporting various
                information about its inputs. It is sent every seconds (for temperature channels).
                Or on change for other digital inputs.
            ";
CM_ SG_ 2147922434 PT1KS_D "Measured temperature sensor on PT1KS_D input.";
CM_ SG_ 2147922434 PT1KS_C "Measured temperature sensor on PT1KS_C input.";
CM_ SG_ 2147922434 PT1K_B "Measured temperature sensor on PT1K_B input.";
CM_ SG_ 2147922434 PT1K_A "
                This input is used as CHAdeMO pistol solenoid input when the controller is configured for CHAdeMO.
                When the controller is configured for MCS, CCS DC or AC, this input can be used as a temperature sensor.
                ";
CM_ SG_ 2147922434 CPU_Temperature1 "Temperature reported by the CPU chip of the charge controller.";
CM_ SG_ 2147922434 CPU_Temperature0 "Temperature reported by the CPU chip of the charge controller.";
CM_ SG_ 2147922434 Reserved "Reserved bits for future uses.";
CM_ SG_ 2147922434 Digital_Input4 "
                    Reports the logical state of DIG_IN4 (CONN6, position 4).
                    Needs to be declared as monitored in `/srv/config.cfg`:

                        [hardware]
                        dig_in4 = Monitor
                ";
CM_ SG_ 2147922434 Digital_Input3 "
                    Reports the logical state of DIG_IN3 (CONN6, position 3).
                    Needs to be declared as monitored in `/srv/config.cfg`:

                        [hardware]
                        dig_in3 = Monitor
                ";
CM_ SG_ 2147922434 Digital_Input2 "
                    Reports the logical state of DIG_IN2 (CONN6, position 2).
                    Needs to be declared as monitored in `/srv/config.cfg`:

                        [hardware]
                        dig_in2 = Monitor
                ";
CM_ SG_ 2147922434 Digital_Input1 "
                    Reports the logical state of DIG_IN1 (CONN6, position 1).
                    Needs to be declared as monitored in `/srv/config.cfg`:

                        [hardware]
                        dig_in1 = Monitor
                ";
CM_ BO_ 2147922435 "
            Extra information from CCS (for information only).  
            !!! info
                    Available since version 4.2
            ";
CM_ SG_ 2147922435 Reserved "Reserved bits for future uses.";
CM_ SG_ 2147922435 CP_Duty_Cycle "Measured PWM duty cycle on the CP line.";
CM_ SG_ 2147922435 CP_State "Measured CP state.";
CM_ BO_ 2147922436 "
            Extra information from MCS (for information only).  
            !!! info
                    Available since version 4.2
            ";
CM_ SG_ 2147922436 Reserved "Reserved bits for future uses.";
CM_ SG_ 2147922436 ID_State "Measured ID state.";
CM_ SG_ 2147922436 CE_State "Measured CE state.";
CM_ BO_ 2147922688 "
               OCPP information needed for power transfer
            ";
CM_ SG_ 2147922688 Dynamic_Target_Current "
                    This signal is useful only during power transfer using CCS ISO15118-20 Dynamic mode.
                    As the charger negociates a current range with the vehicle, a third party needs to specify
                    the current setpoint within that range.
                    OCPP1.6J was adapted to provide this inforamtion.
                ";
CM_ BO_ 2147922944 "
                Error codes currently raised by the charge controller. One bit per code, several
                can be set at once. Codes are named after DIN DKE SPEC 99003 wherever the
                specification defines one.

                Sent every second, and immediately whenever a code is raised or cleared, so
                the codes currently raised can be read at any time rather than only at the moment
                they change.

                How long a code stays raised is one of two behaviours, chosen per pistol in
                the controller's config file:

                - **Kept until the next session**, the default. A code outlives the session
                  that raised it: it stays raised through the return to idle and is cleared
                  only when the next plug-in starts a new session. 
                  whenever __Advantics_Controller_Status.State__ reads __Waiting_For_PEV__,
                  a code set here belongs to the session that has just finished. It tells you
                  why that session ended, not that something is wrong with the charger right now.
                - **Cleared on the way back to idle**, with the config entry 
                  `clear_error_codes_on_idle = true` in the pistol section.
                  A code is dropped as soon as the controller cycles
                  back to __Waiting_For_PEV__, so it is never visible outside the session
                  that raised it.

                Live status, such as which limit the charge is currently held to, is in
                <<Charger_Status_Flags>> instead, so a listener of these codes is never woken up
                by a status change.

                The pilot-line and V2G codes only apply to CCS and MCS sessions, and the __EV*__
                ones report what the vehicle declared about itself in DC_EVStatus.EVErrorCode
                (DIN SPEC 70121 and DIN EN ISO 15118-2 only).
            ";
CM_ SG_ 2147922944 Reserved_Flags "Reserved bits for future uses.";
CM_ SG_ 2147922944 PowerPermitWithdrawn "The vehicle stopped granting its hardware power permit while power transfer was
                    in progress. Not reported when the permit drops at the normal end of
                    a charge.";
CM_ SG_ 2147922944 SessionStoppedBeforeCharge "The session ended before the charge phase started: the vehicle was connected and
                    communicating, but the charger never delivered power. Says that a
                    session was lost early, not why -- any code raised alongside it is
                    the reason. On its own it means the vehicle or the operator ended
                    it, or the negotiation never completed.";
CM_ SG_ 2147922944 EVChargingSystemIncompatibility "Vehicle reports DC_EVStatus.EVErrorCode = FAILED_ChargingSystemIncompatibility.";
CM_ SG_ 2147922944 EVChargingVoltageOutOfRange "Vehicle reports DC_EVStatus.EVErrorCode = FAILED_ChargingVoltageOutOfRange.";
CM_ SG_ 2147922944 EVChargingCurrentDifferential "Vehicle reports DC_EVStatus.EVErrorCode = FAILED_ChargingCurrentdifferential.";
CM_ SG_ 2147922944 EVRESSMalfunction "Vehicle reports DC_EVStatus.EVErrorCode = FAILED_EVRESSMalfunction.";
CM_ SG_ 2147922944 EVConnectorLockFault "Vehicle reports DC_EVStatus.EVErrorCode = FAILED_ChargerConnectorLockFault.";
CM_ SG_ 2147922944 EVShiftPosition "Vehicle reports DC_EVStatus.EVErrorCode = FAILED_EVShiftPosition.";
CM_ SG_ 2147922944 EVRESSTemperatureInhibit "Vehicle reports DC_EVStatus.EVErrorCode = FAILED_RESSTemperatureInhibit.";
CM_ SG_ 2147922944 CommunicationSetupTimeout "The vehicle did not complete the session setup within the time allowed by
                    `communication_setup_timeout`, counted from the communication link coming up.";
CM_ SG_ 2147922944 V2GProtocolNotAllowed "The negotiated application protocol is disabled, or not allowed over this connection.";
CM_ SG_ 2147922944 V2GParameterNotSupported "The application protocol the vehicle asked for is not supported.
                    DIN DKE SPEC 99003 use case 8.4.";
CM_ SG_ 2147922944 V2GSessionIDUnexpected "The vehicle used a session ID we do not know.";
CM_ SG_ 2147922944 V2GSequenceError "The vehicle sent a request that is not allowed in the current sequence state.";
CM_ SG_ 2147922944 ChargeEnableStateUnexpected "Charge Enable is in a valid state, but not one the charging sequence allows at that
                    point, such as leaving C while power is being transferred or dropping
                    to A with a session still running. Readings the sequence treats as
                    noise are not reported.";
CM_ SG_ 2147922944 ChargeEnableFault "The MCS Charge Enable line is in error state E. The line itself is at fault.";
CM_ SG_ 2147922944 ControlPilotStateUnexpected "Control Pilot is in a valid state, but not one the charging sequence allows at that
                    point: B where C or D is required, C or D where only B is, or a drop
                    to A with a session still running. The normal unplug once a session
                    has ended is not reported.";
CM_ SG_ 2147922944 ControlPilotFault "The CCS Control Pilot line is in an error state: E (0 V) or F, the charger
                    signalling itself unavailable. The line itself is at fault.";
CM_ SG_ 2147922944 BidirectionalNotSupported "The vehicle requested discharge from a charger that is not bidirectional.";
CM_ SG_ 2147922944 RangeModeNotSupported "Range mode setpoints were requested from a charger configured without range mode.";
CM_ SG_ 2147922944 CANBusError "Sending on the power modules CAN bus failed.";
CM_ SG_ 2147922944 NodeDisconnected "A required controller application stopped answering its heartbeat.";
CM_ SG_ 2147922944 InternalError "An unhandled error occurred inside the controller.";
CM_ SG_ 2147922944 ChargerSequenceError "The power modules refused a state transition the controller asked for.";
CM_ SG_ 2147922944 HighTemperature "A monitored temperature crossed its charge-stop threshold.";
CM_ SG_ 2147922944 PowerModuleRampDownTimeout "The power modules did not bring the output current down in time when the charge
                    ended. The contactors were left closed.";
CM_ SG_ 2147922944 PowerModuleDisabled "The power modules withdrew Power_Modules_Status.System_Enable during a powered phase.";
CM_ SG_ 2147922944 PowerModuleCANTimeout "No Power_Modules_Status received within the configured timeout.";
CM_ SG_ 2147922944 PowerModuleFault "The power modules are in a fault or defective state.";
CM_ SG_ 2147922944 InsulationMonitorFault "The insulation monitoring device reports an internal device error. Distinct from
                    InsulationFault, which is the measured resistance being too low.";
CM_ SG_ 2147922944 InsulationFault "Insulation resistance is below the allowed limit.";
CM_ SG_ 2147922944 ConnectorLockFailure "The connector lock driver reports a fault. AC charging only.";
CM_ SG_ 2147922944 OutputDriverFault "The industrial digital output driver reports a fault.";
CM_ SG_ 2147922944 EmergencyStopLoopOpen "The emergency stop current loop is open.";
CM_ SG_ 2147922944 InterlockFault "The interlock protection input is pulled low. Any safety device wired to that
                    line can pull it down to stop the charge. Causes that have their own code
                    are excluded here: the emergency stop loop, the industrial output driver,
                    and the controller pulling the line low itself.";
CM_ BO_ 2147922945 "
                Live status flags of the charge controller. One bit per flag, several can be set
                at once. During a charge session, a flag can be set then goes back to 0 on its own
                once its condition is gone.

                Sent every second, and immediately whenever a flag changes.

                - When two limits give the same value, both flags are set.
                - The same flags cover charging and discharging, and in range mode they cover
                  both ends of the range at once.
                - A power limit becomes a current limit once divided by the present voltage, so
                  which limit is the lowest can change as the voltage moves. Several frames may
                  follow in quick succession when it does.

            ";
CM_ SG_ 2147922945 Reserved_Flags "Reserved bits for future uses.";
CM_ SG_ 2147922945 VehicleCurrentLimit "The maximum current the vehicle declared is what holds the current down, below every
                    limit of our own. DC only.";
CM_ SG_ 2147922945 OCPPCurrentLimit "The limit set by OCPP smart charging is what holds the current down, either as a
                    current or as a power divided by the present voltage. Applies to charging, not
                    discharging.";
CM_ SG_ 2147922945 CableTemperatureDerating "A monitored temperature is derating the cable's current limit. Set whenever that
                    derating applies, whether or not it is what holds the current down.";
CM_ SG_ 2147922945 CableVoltageLimit "The cable's own rated voltage (`max_cable_voltage`) is what holds the target voltage
                    below what the vehicle asked for. DC only.";
CM_ SG_ 2147922945 CableCurrentLimit "The cable's own rating is what holds the current down: `max_cable_current`, or
                    `max_cable_power` divided by the present voltage. On AC,
                    `max_cable_phase_current`.";
CM_ SG_ 2147922945 ChargerTemperatureDerating "A monitored temperature is derating the charger's current limit. Set whenever that
                    derating applies, whether or not it is what holds the current down: it is a real
                    reduction of what the charger can do.";
CM_ SG_ 2147922945 ChargerVoltageLimit "The charger's own rated voltage (`max_charger_voltage`, or a lower limit the power
                    modules report) is what holds the target voltage below what the vehicle asked
                    for. DC only.";
CM_ SG_ 2147922945 ChargerCurrentLimit "The charger's own rating is what holds the current down: `max_charger_current`,
                    `max_charger_power` divided by the present voltage, their discharge
                    counterparts, or a lower limit the power modules report. On AC,
                    `max_charger_phase_current`.";
CM_ BO_ 2147922946 "
                What the insulation monitor the charge controller reads itself is measuring.

                Sent every second, and only when the controller is configured to read a supported
                insulation monitor. A charger that measures the insulation itself, and reports it
                in <<Power_Modules_Status.Insulation_Resistance>>, never sees this message: the
                value is already its own.

                This is a reading, not a verdict. The outcome of the insulation test is the charge
                sequence moving on, and a failure is reported as __InsulationFault__ or
                __InsulationMonitorFault__ in <<Charger_Diagnostic_Status>>.
            ";
CM_ SG_ 2147922946 Reserved "Reserved bits for future uses.";
CM_ SG_ 2147922946 Device_Status "
                    What the device says about itself and about the resistance it measures,
                    ordered from no news to worst news.

                    The first two are the controller's own answers rather than the device's,
                    and are the two that mean there is no measurement:

                    - __Not_Available__: no insulation monitor is being read at all. It cannot
                      appear on this message, which is only sent when one is.
                    - __No_Communication__: a monitor is configured and is not answering --
                      not yet, or not any more. A silent device is not a faulty one, so this is
                      not reported as __Device_Error__.

                    __Prewarning__, __Warning__ and __Alarm__ are the device telling you about
                    the resistance, and the measurement stands. __Device_Error__ is the device
                    reporting a fault of its own, and then there is no measurement: on a device
                    error this ISOMETER re-purposes its measurement channels to report earth
                    and system connection instead of resistance and voltage.
                ";
CM_ SG_ 2147922946 Voltage "
                    Voltage measured by the device on the line it watches. This is its own
                    measurement, independent of the charger's, so it can be compared against
                    <<Power_Modules_Status.Present_Voltage>>.

                    65535 means there is no measurement to report.
                ";
CM_ SG_ 2147922946 Resistance "
                    Insulation resistance measured by the device.

                    65535 means there is no measurement to report, which is also what
                    __Device_Status__ then says. It is never reported as 0, which would read as a
                    dead short.
                ";
CM_ BO_ 2147889152 "
                Periodic message reporting the current status of power modules. This message should
                be sent all the time when power modules are running.

                [IMPORTANT]
                ====
                Controller implements a timeout on the reception of this message. It is used as a
                source of interlock condition. As such, this interlock source is evaluated only in
                states where power modules should be alive.

                Therefore, it is NOT evaluated when waiting for a PEV to plug-in, or when
                negotiating the connection with the PEV.

                Power modules should be alive from the moment <<New_Charge_Session>> is sent, until
                <<Charge_Session_Finished>> is sent. At any other time, power modules are allowed to
                sleep and not send this message.
                ====
            ";
CM_ SG_ 2147889152 Insulation_Resistance "
                    Reports the current insulation resistance, in multiple of 2 kOhms.

                    TIP: If the RCD sensor only gives a boolean value, then 255 correspond to a __Valid__
                    insulation, and 0 to an __Invalid__ insulation.

                    IMPORTANT: Whenever a power function is used after the insulation test, if this
                    signal reports an insulation resistance below the limit of 100 Ohms/V, then this
                    is considered as an interlock condition and an emergency stop is carried out.
                ";
CM_ SG_ 2147889152 System_Enable "
                        Tells if charging is allowed.

                        When <<New_Charge_Session>> is sent, the controller waits for this signal
                        to be 1 to continue the charge sequence.

                        If 0 is emitted between <<New_Charge_Session>> and before the charging loop
                        starts, the charge controller tells the vehicle the charging service is
                        unavailable.

                        If 0 is emitted during the charging loop, this is interpreted as an
                        emergency shutdown requested by power modules.
                ";
CM_ SG_ 2147889152 Enclosure_Temperature "Top temperature sensed in the enclosure.";
CM_ SG_ 2147889152 Power_Modules_Temperature "Top temperature sensed in power modules.";
CM_ SG_ 2147889152 Present_Current "Current measurement at the output of the charger";
CM_ SG_ 2147889152 Present_Voltage "Voltage measurement at the output of the charger";
CM_ BO_ 2147889153 "
                Message to dynamically set parameters of power transfer (limits, forced setpoints).
                This message can be sent as often as needed (but not faster than 100ms).
            ";
CM_ SG_ 2147889153 Range_Target_Current "
                    This signal is useful only for chargers using one of the supported power module
                    interface (ie. we directly control power modules), plus the generic interface
                    as a mean of external control.

                    When <<DC_Power_Control.Setpoints_Mode>> == __Range_Mode__, and power modules
                    are of a kind that cannot decide of the load current by themselves, by default
                    the maximum of the range will be used.

                    With this signal, you can set a different target setpoint that will be send to
                    power modules. Direction of power transfers is chosen with the sign of this
                    signal. When the sign changes, a switch over will happen.

                    Values are always capped to the allowed range given in <<DC_Power_Control>>.
                    Provided values will also be ramped up or down, using ramp slopes defined by
                    config file entries `current_ramp_up_rate` and `current_ramp_down_rate`.

                    Note that the actual setpoint sent to power modules is not reflected in
                    <<DC_Power_Control>> message, as values in this message need to keep
                    reflecting the full allowed range. Ie. <<DC_Power_Control>> will not emulate
                    a __Target_Mode__, and it will still show the normal __Range_Mode__.

                    Note also that while the same functionality could be achieved by changing
                    <<Power_Transfer_Parameters.Maximum_Charge_Current>>, this Range_Target_Current
                    signal is actually entirely internal, and the value is never directly reported
                    to the vehicle. Which mean Maximum_Charge_Current can still reflect the true
                    maximum charge current advertised to the vehicle.

                    This signal does nothing in the following situations:
                    - <<DC_Power_Control.Setpoints_Mode>> == __Target_Mode__.
                    - Or you only use the generic interface, and manage power modules yourself.
                ";
CM_ SG_ 2147889153 Maximum_Discharge_Current "
                    Maximum discharge current of the charger, reported to the vehicle.

                    Value is capped by limit statically defined in config file.
                    If set to 0, then it means to use default `max_charger_discharge_current` from
                    config file.
                ";
CM_ SG_ 2147889153 Maximum_Charge_Current "
                    Maximum charge current of the charger, reported to the vehicle.

                    Value is capped by limit statically defined in config file.
                    If set to 0, then it means to use default `max_charger_current` from config file.
                ";
CM_ SG_ 2147889153 Maximum_Voltage "
                    Maximum output voltage of the charger, reported to the vehicle.

                    Value is capped by limit statically defined in config file.
                    If set to 0, then it means to use default `max_charger_voltage` from config file.
                ";
CM_ BO_ 2147889154 "
                This message has most flags controlling the charge sequence (apart from System_Enable).

                The first byte is for flags having effect before a charge session starts.
                The second byte is for flags having effect during parameters negotiation.
                The third byte is for flags having effect during power stages (insulation test,
                precharge and charging).

                The controller config file should have the entry \"use_sequence_flags = true\" in the
                \"[charger]\" section in order to take them into account.

                To make sure the controller is taking a first message as initialisation of these
                flags, send this first message after Advantics_Controller_Status message reports a
                State of Waiting_For_PEV (value 1).

                All signals default to value 0. Bits that are not used in this version should remain
                at 0 to avoid incompatibility with future versions.
            ";
CM_ SG_ 2147889154 User_Stop_Button "Simulate a press on the user stop button (for normal charge termination). Only acts on change (so you need to cycle it back to 0).";
CM_ SG_ 2147889154 Charge_Parameters_Done "Tells when fields in Power_Transfer_Parameters message can be considered stable and sent to the vehicle.";
CM_ SG_ 2147889154 CCS_Authorisation_Valid "Tells if authorisation of vehicle is valid (CCS only). Only meaningful when CCS_Authorisation_Done is 1.";
CM_ SG_ 2147889154 CCS_Authorisation_Done "Tells if authorisation of vehicle is finished (CCS only)";
CM_ SG_ 2147889154 CHAdeMO_Start_Button "Simulate a press on the CHAdeMO start button. Only acts on change (so you need to cycle it back to 0).";
CM_ SG_ 2147889154 Start_Charge_Authorisation "
                    Indicate if the controller should even attempt to start a charge session.
                    Suitable for external authorisation permit that happens before user is allowed
                    to plug or start a charge.

                    Set to 0 to disallow charging, and 1 to allow.

                    In CCS, it will keep CP PWM to 100%, even when detecting State B (9V).
                    In CHAdeMO, it will simply ignore the start button.
                    But in both case, it will register the user intent as wanting to charge. As soon
                    as this flag allows charging, it will then start the charge session.
                ";
CM_ BO_ 2147889665 "
                Controller (ADM-CS-SECC hardware variant, ie. \"DIN rail\") has various outputs that
                can be controlled through this message.
            ";
CM_ SG_ 2147889665 Reserved "Reserved bits for future uses.";
CM_ SG_ 2147889665 Led3 "
                    Sets the brightness of LED3 (CON5 7) in a scale from 1 to 100.
                    Greater values than 100 will be treated as max brigthness.

                        [hardware]
                        led3 = CAN_Controlled
                ";
CM_ SG_ 2147889665 Led2 "
                    Sets the brightness of LED2 (CON5 6) in a scale from 1 to 100.
                    Greater values than 100 will be treated as max brigthness.

                        [hardware]
                        led2 = CAN_Controlled
                ";
CM_ SG_ 2147889665 Led1 "
                    Sets the brightness of LED1 (CON5 5) in a scale from 1 to 100. 
                    Greater values than 100 will be treated as max brigthness.

                        [hardware]
                        led1 = CAN_Controlled
                ";
CM_ SG_ 2147889665 Digital_Output4 "
                    Reports the logical state of DIG_OUT4 (CONN5, position 4).
                    Needs to be declared as CAN Controlled in `/srv/config.cfg`:

                        [hardware]
                        dig_out4 = CAN_Controlled
                ";
CM_ SG_ 2147889665 Digital_Output3 "
                    Reports the logical state of DIG_OUT3 (CONN5, position 3).
                    Needs to be declared as CAN Controlled in `/srv/config.cfg`:

                        [hardware]
                        dig_out3 = CAN_Controlled
                ";
CM_ SG_ 2147889665 Digital_Output2 "
                    Reports the logical state of DIG_OUT2 (CONN5, position 2).
                    Needs to be declared as CAN Controlled in `/srv/config.cfg`:

                        [hardware]
                        dig_out2 = CAN_Controlled
                ";
CM_ SG_ 2147889665 Digital_Output1 "
                    Sets the logical state of DIG_OUT1 (CONN5, position 1).
                    Needs to be declared as CAN Controlled in `/srv/config.cfg`:

                        [hardware]
                        dig_out1 = CAN_Controlled
                ";
CM_ BO_ 2147889666 "
                Controller (ADM-CS-SPCC hardware variant) has various outputs that
                can be controlled through this message.
            ";
CM_ SG_ 2147889666 Reserved "Reserved bits for future uses.";
CM_ SG_ 2147889666 Led3 "
                    Sets the brightness of LED3 (CON105 13) in a scale from 1 to 100.
                    Greater values than 100 will be treated as max brigthness.

                        [hardware]
                        led3 = CAN_Controlled
                ";
CM_ SG_ 2147889666 Led2 "
                    Sets the brightness of LED2 (CON105 12) in a scale from 1 to 100.
                    Greater values than 100 will be treated as max brigthness.

                        [hardware]
                        led2 = CAN_Controlled
                ";
CM_ SG_ 2147889666 Led1 "
                    Sets the brightness of LED1 (CON105 11) in a scale from 1 to 100. 
                    Greater values than 100 will be treated as max brigthness.

                        [hardware]
                        led1 = CAN_Controlled
                ";
CM_ SG_ 2147889666 Digital_Output2 "
                    Reports the logical state of DIG_OUT2 (CONN5, position 2).
                    Needs to be declared as CAN Controlled in the config file:

                        [hardware]
                        dig_out2 = CAN_Controlled
                ";
CM_ SG_ 2147889666 Digital_Output1 "
                    Sets the logical state of DIG_OUT1 (CONN5, position 1).
                    Needs to be declared as CAN Controlled in the config file:

                        [hardware]
                        dig_out1 = CAN_Controlled
                ";
BA_DEF_ BO_  "GenMsgCycleTime" INT 0 65535;
BA_DEF_  "Baudrate" INT 0 10485760;
BA_DEF_DEF_  "GenMsgCycleTime" 0;
BA_DEF_DEF_  "Baudrate" 125000;
BA_ "Baudrate" 500000;
BA_ "GenMsgCycleTime" BO_ 2147921920 100;
BA_ "GenMsgCycleTime" BO_ 2147921921 100;
BA_ "GenMsgCycleTime" BO_ 2147921923 100;
BA_ "GenMsgCycleTime" BO_ 2147921925 100;
BA_ "GenMsgCycleTime" BO_ 2147921926 1000;
BA_ "GenMsgCycleTime" BO_ 2147921927 1000;
BA_ "GenMsgCycleTime" BO_ 2147921928 1000;
BA_ "GenMsgCycleTime" BO_ 2147921929 1000;
BA_ "GenMsgCycleTime" BO_ 2147921930 1000;
BA_ "GenMsgCycleTime" BO_ 2147921931 1000;
BA_ "GenMsgCycleTime" BO_ 2147922181 1000;
BA_ "GenMsgCycleTime" BO_ 2147922432 1000;
BA_ "GenMsgCycleTime" BO_ 2147922433 1000;
BA_ "GenMsgCycleTime" BO_ 2147922434 1000;
BA_ "GenMsgCycleTime" BO_ 2147922435 100;
BA_ "GenMsgCycleTime" BO_ 2147922436 100;
BA_ "GenMsgCycleTime" BO_ 2147922944 1000;
BA_ "GenMsgCycleTime" BO_ 2147922945 1000;
BA_ "GenMsgCycleTime" BO_ 2147922946 1000;
BA_ "GenMsgCycleTime" BO_ 2147889152 100;
BA_ "GenMsgCycleTime" BO_ 2147889665 1000;
BA_ "GenMsgCycleTime" BO_ 2147889666 1000;
VAL_ 2147921920 State 0 "Initialising" 1 "Waiting_For_PEV" 2 "Negotiating_Connection" 3 "Connected_With_Full_Info" 4 "Insulation_Test" 5 "Precharge" 6 "Waiting_For_Charge" 7 "Charging" 8 "Ending_Charge" 9 "Welding_Detection" 10 "Closing_Communication" 11 "CCS_Authorisation_Process" 12 "Not_Available" 13 "Charge_Pause" ;
VAL_ 2147921921 Plug_and_pins 0 "CCS_DC_Core" 1 "CCS_DC_Extended" 2 "CHAdeMO" 3 "CCS_AC" 4 "MCS" ;
VAL_ 2147921921 Communication_Protocol 0 "CCS_DIN_70121_2012_v2" 1 "CCS_ISO_15118_2010_v1" 2 "CCS_ISO_15118_2013_v2" 3 "CHAdeMO_v0.9" 4 "CHAdeMO_v1.0-v1.1-v1.2" 5 "CHAdeMO_v2.0" 6 "CCS_PWM" 7 "CCS_ISO_15118_2022" ;
VAL_ 2147921922 Vehicle_Ready_for_Charging 0 "Charge_Stopped" 1 "Charge_Started" ;
VAL_ 2147921923 Lower_Output_Voltage 0 "No_Lowering" 1 "Lowering" ;
VAL_ 2147921923 Output_Contactors 0 "Open" 1 "Close" ;
VAL_ 2147921923 Setpoints_Mode 0 "Target_Mode" 1 "Range_Mode" ;
VAL_ 2147921923 Power_Function 0 "Off" 1 "Standby" 2 "Insulation_Test" 4 "Precharge" 8 "Power_Transfer" ;
VAL_ 2147921924 State 0 "Clean_Stop" 1 "Rushed_Stop" ;
VAL_ 2147921925 Origin 1 "EVSE" 3 "PEV" ;
VAL_ 2147921926 CSM_Version_Type 0 "None" 1 "dev" 2 "rc" 3 "post" ;
VAL_ 2147921927 EVSE_Controller_Version_Type 0 "None" 1 "dev" 2 "rc" 3 "post" ;
VAL_ 2147921928 CCS_SECC_Version_Type 0 "None" 1 "dev" 2 "rc" 3 "post" ;
VAL_ 2147921929 Chademo_SECC_Version_Type 0 "None" 1 "dev" 2 "rc" 3 "post" ;
VAL_ 2147921930 OCPP_Charge_Point_Version_Type 0 "None" 1 "dev" 2 "rc" 3 "post" ;
VAL_ 2147921931 SLAC_EVSE_Version_Type 0 "None" 1 "dev" 2 "rc" 3 "post" ;
VAL_ 2147922435 CP_State 0 "E_or_F" 3 "D" 6 "C" 9 "B" 12 "A" ;
VAL_ 2147922436 ID_State 0 "Unmated" 1 "Mated" 2 "Mated_EVAux" 3 "Mated_EVSEAux" ;
VAL_ 2147922436 CE_State 0 "Undefined" 1 "A" 2 "B0" 3 "B0_Aux" 4 "B" 5 "B_Aux" 6 "C" 7 "C_Aux" 8 "EC" 9 "E" ;
VAL_ 2147922946 Device_Status 0 "Not_Available" 1 "No_Communication" 2 "OK" 3 "Prewarning" 4 "Warning" 5 "Alarm" 6 "Device_Error" ;
VAL_ 2147889152 System_Enable 0 "Not_Allowed" 1 "Allowed" ;
VAL_ 2147889154 User_Stop_Button 0 "Not_Pressed" 1 "Pressed" ;
VAL_ 2147889154 Charge_Parameters_Done 0 "Not_Done" 1 "Done" ;
VAL_ 2147889154 CCS_Authorisation_Valid 0 "Invalid" 1 "Valid" ;
VAL_ 2147889154 CCS_Authorisation_Done 0 "Not_Done" 1 "Done" ;
VAL_ 2147889154 CHAdeMO_Start_Button 0 "Not_Pressed" 1 "Pressed" ;
VAL_ 2147889154 Start_Charge_Authorisation 0 "Not_Allowed" 1 "Allowed" ;
